AUTOSAR XML (schema 4-2-2)
package /Pack_sw_Types
  constant specification CONST_0c0f918b8f394b8586f853bd5: value-spec=CONST_0c0f918b8f394b8586f853bd5:0
  constant specification CONST_951406b330e947ed9394eb477: value-spec=CONST_951406b330e947ed9394eb477:0
  impl type ComM_ModeType: compu {0=NO_COMMUNICATION, 1=SILENT_COMMUNICATION, 2=FULL_COMMUNICATION}, implementation-data-type=uint8
package /RootP_CS
  4 x client server interface:
    ComM_UserRequest: is-service=true
      operation RequestComMode: possible-error=[E_MODE_LIMITATION, E_NOT_OK]
        arg ComMode: type=ComM_ModeType, direction=IN
      error E_MODE_LIMITATION: error-code=2
      error E_NOT_OK: error-code=1
    DETService: is-service=true
      operation ReportError: possible-error=E_OK
        arg InstanceId: type=uint8, direction=IN
        arg ApiId: type=uint8, direction=IN
        arg ErrorId: type=uint8, direction=IN
      error E_OK: error-code=0
    If_CounterModify
      operation SetCounterAndAdd
        arg newCounterValue: type=uint8, direction=IN
        arg returnSum: type=uint8, direction=OUT
    If_DiscreteValueOutput
      operation SetDiscreteValue
        arg value: type=uint8, direction=IN
package /RootP_SR_Data
  sender receiver interface If_Counter
    data CounterValue: type=uint8
  sender receiver interface If_Internal
    data EventMessage: sw-impl-policy=QUEUED, type=uint8
package /RootP_SWC_CyclicCounter
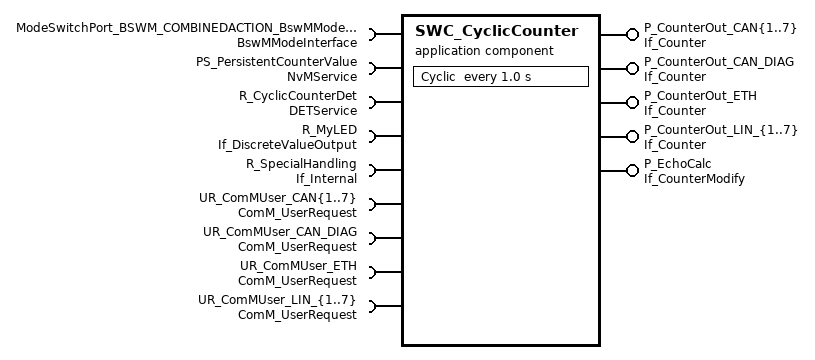
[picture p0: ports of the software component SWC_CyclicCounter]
  application sw component type SWC_CyclicCounter
    require port ModeSwitchPort_BSWM_COMBINEDACTION_BswMMode_PortInterfaces_BswMMode: required-interface=BswMModeInterface
    require port PS_PersistentCounterValue: required-interface=NvMService
    17 x provide port:
      P_CounterOut_CAN{1..7}: nonqueued-sender-com-spec{data-element=CounterValue, init-value=0}, provided-interface=If_Counter
      P_CounterOut_CAN_DIAG: nonqueued-sender-com-spec{data-element=CounterValue, init-value=0}, provided-interface=If_Counter
      P_CounterOut_ETH: nonqueued-sender-com-spec{data-element=CounterValue, init-value=0}, provided-interface=If_Counter
      P_CounterOut_LIN_{1..7}: nonqueued-sender-com-spec{data-element=CounterValue, init-value=0}, provided-interface=If_Counter
      P_EchoCalc: server-com-spec{operation=SetCounterAndAdd, queue-length=1}, provided-interface=If_CounterModify
    19 x require port:
      R_CyclicCounterDet: required-interface=DETService
      R_MyLED: required-interface=If_DiscreteValueOutput
      R_SpecialHandling: queued-receiver-com-spec{data-element=EventMessage, queue-length=8}, required-interface=If_Internal
      UR_ComMUser_CAN{1..7}: required-interface=ComM_UserRequest
      UR_ComMUser_CAN_DIAG: required-interface=ComM_UserRequest
      UR_ComMUser_ETH: required-interface=ComM_UserRequest
      UR_ComMUser_LIN_{1..7}: required-interface=ComM_UserRequest
    behavior IB_SWC_CyclicCounter: data-type-mapping=BswMModeMapping, handle-termination-and-restart=NO-SUPPORT
      timing event CyclicEvent: start-on-event=Cyclic, period=1.0
        disabled-mode:
          ModeSwitchPort_BSWM_COMBINEDACTION_BswMMode_PortInterfaces_BswMMode.BswMMode.BSWM_GO_OFF_ONE_A
          ModeSwitchPort_BSWM_COMBINEDACTION_BswMMode_PortInterfaces_BswMMode.BswMMode.BSWM_PRP_SHUTDOWN
          ModeSwitchPort_BSWM_COMBINEDACTION_BswMMode_PortInterfaces_BswMMode.BswMMode.BSWM_STARTUP_TWO_A
          ModeSwitchPort_BSWM_COMBINEDACTION_BswMMode_PortInterfaces_BswMMode.BswMMode.BSWM_STARTUP_TWO_B
          ModeSwitchPort_BSWM_COMBINEDACTION_BswMMode_PortInterfaces_BswMMode.BswMMode.BSWM_WAKEUP_TWO
      swc mode switch event ModeSwitchedPrpShutdown: start-on-event=Shutdown, activation=ON-ENTRY, mode=ModeSwitchPort_BSWM_COMBINEDACTION_BswMMode_PortInterfaces_BswMMode.BswMMode.BSWM_PRP_SHUTDOWN
      swc mode switch event ModeSwitchedRunTwo: start-on-event=Init, activation=ON-ENTRY, mode=ModeSwitchPort_BSWM_COMBINEDACTION_BswMMode_PortInterfaces_BswMMode.BswMMode.BSWM_RUN_TWO
      operation invoked event SetCounterOperationInvoked: start-on-event=SetCounter, operation=P_EchoCalc.SetCounterAndAdd
      explicit-inter-runnable-variables:
        data CurrentCounterValue: type=uint8, init-value=0
      per instance memory PimCounterValue: init-value=99, type=CounterValueType, type-definition=uint8
      per-instance-parameters:
        parameter data prototype PrmCounterValue: type=uint8, init-value=99
      port-api-options:
        enable-take-address=false, indirect-api=false, port=P_EchoCalc
        enable-take-address=false, indirect-api=false, port=P_CounterOut_CAN{1..7}
        enable-take-address=false, indirect-api=false, port=P_CounterOut_CAN_DIAG
        enable-take-address=false, indirect-api=false, port=P_CounterOut_LIN_{1..7}
        enable-take-address=false, indirect-api=false, port=P_CounterOut_ETH
      4 x runnable:
        Cyclic: symbol=SWC_CyclicCounter_Cyclic
          data-receive-point-by-arguments:
            access DRP_P_Special_EventMessage: accessed-variable=R_SpecialHandling.EventMessage
          data-send-points:
            16 x access:
              DWA_P_CounterOut_CAN{1..7}_CounterValue: accessed-variable=P_CounterOut_CAN{1..7}.CounterValue
              DWA_P_CounterOut_CAN_DIAG_CounterValue: accessed-variable=P_CounterOut_CAN_DIAG.CounterValue
              DWA_P_CounterOut_ETH_CounterValue: accessed-variable=P_CounterOut_ETH.CounterValue
              DWA_P_CounterOut_LIN_{1..7}_CounterValue: accessed-variable=P_CounterOut_LIN_{1..7}.CounterValue
          read-local-variables:
            access CurrentCounterValue3: accessed-variable=CurrentCounterValue
          18 x sync call, all with timeout=0.0:
            CS_DETService_ReportError: operation=R_CyclicCounterDet.ReportError
            CS_EchoResult_SetCounterAndAdd: operation=R_MyLED.SetDiscreteValue
            CS_UR_ComMUser_CAN{1..7}_ComM_UserRequest: operation=UR_ComMUser_CAN{1..7}.RequestComMode
            CS_UR_ComMUser_CAN_DIAG_ComM_UserRequest: operation=UR_ComMUser_CAN_DIAG.RequestComMode
            CS_UR_ComMUser_ETH_ComM_UserRequest: operation=UR_ComMUser_ETH.RequestComMode
            CS_UR_ComMUser_LIN_{1..7}_ComM_UserRequest: operation=UR_ComMUser_LIN_{1..7}.RequestComMode
          written-local-variables:
            access CurrentCounterValue4: accessed-variable=CurrentCounterValue
        Init: symbol=SWC_CyclicCounter_Init
          parameter access PA_PersistentCounterValue: accessed-parameter=PrmCounterValue
          16 x sync call, all with timeout=0.0:
            CS_UR_ComMUser_CAN{1..7}_ComM_UserRequest: operation=UR_ComMUser_CAN{1..7}.RequestComMode
            CS_UR_ComMUser_CAN_DIAG_ComM_UserRequest: operation=UR_ComMUser_CAN_DIAG.RequestComMode
            CS_UR_ComMUser_ETH_ComM_UserRequest: operation=UR_ComMUser_ETH.RequestComMode
            CS_UR_ComMUser_LIN_{1..7}_ComM_UserRequest: operation=UR_ComMUser_LIN_{1..7}.RequestComMode
          written-local-variables:
            access CurrentCounterValue: accessed-variable=CurrentCounterValue
        SetCounter: can-be-invoked-concurrently=true, symbol=SWC_CyclicCounter_SetCounter
          read-local-variables:
            access CurrentCounterValue1: accessed-variable=CurrentCounterValue
          written-local-variables:
            access CurrentCounterValue2: accessed-variable=CurrentCounterValue
        Shutdown: symbol=SWC_CyclicCounter_Shutdown
          read-local-variables:
            access CurrentCounterValue3: accessed-variable=CurrentCounterValue
package /RootP_SWC_IoHwAbs
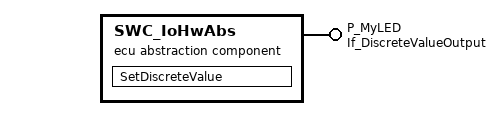
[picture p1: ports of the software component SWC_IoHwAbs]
  ecu abstraction sw component type SWC_IoHwAbs
    provide port P_MyLED: server-com-spec{operation=SetDiscreteValue, queue-length=1}, provided-interface=If_DiscreteValueOutput
    behavior IB_SWC_IoHwAbs: handle-termination-and-restart=NO-SUPPORT, port-api-option{enable-take-address=false, indirect-api=false, port-defined-argument-value{value=0, value-type=uint32}, port=P_MyLED}
      operation invoked event SetDiscreteValueOperationInvoked: start-on-event=SetDiscreteValue, operation=P_MyLED.SetDiscreteValue
      runnable SetDiscreteValue: can-be-invoked-concurrently=true, symbol=SWC_IoHwAbs_SetDiscreteValue
package /RootP_SWC_ModifEcho
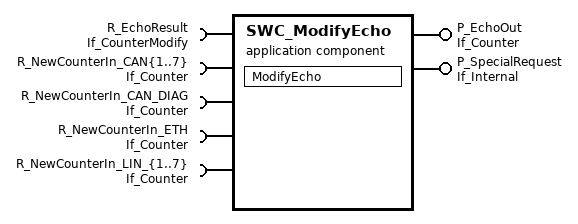
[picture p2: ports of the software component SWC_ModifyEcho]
  application sw component type SWC_ModifyEcho
    provide port P_EchoOut: nonqueued-sender-com-spec{data-element=CounterValue, init-value=0}, provided-interface=If_Counter
    provide port P_SpecialRequest: provided-interface=If_Internal
    17 x require port:
      R_EchoResult: required-interface=If_CounterModify
      R_NewCounterIn_CAN{1..7}: nonqueued-receiver-com-spec{data-element=CounterValue, init-value=constant-reference=CONST_0c0f918b8f394b8586f853bd5}, required-interface=If_Counter
      R_NewCounterIn_CAN_DIAG: nonqueued-receiver-com-spec{data-element=CounterValue, init-value=constant-reference=CONST_0c0f918b8f394b8586f853bd5}, required-interface=If_Counter
      R_NewCounterIn_ETH: nonqueued-receiver-com-spec{data-element=CounterValue, init-value=constant-reference=CONST_0c0f918b8f394b8586f853bd5}, required-interface=If_Counter
      R_NewCounterIn_LIN_{1..7}: nonqueued-receiver-com-spec{data-element=CounterValue, init-value=constant-reference=CONST_0c0f918b8f394b8586f853bd5}, required-interface=If_Counter
    behavior IB_SWC_ModifyEcho: handle-termination-and-restart=NO-SUPPORT
      data received event DataReceivedEvent: start-on-event=ModifyEcho, data=R_NewCounterIn_CAN_DIAG.CounterValue
      port-api-options:
        enable-take-address=false, indirect-api=false, port=R_EchoResult
        enable-take-address=false, indirect-api=false, port=R_NewCounterIn_CAN_DIAG
        enable-take-address=false, indirect-api=false, port=P_EchoOut
      runnable ModifyEcho: symbol=SWC_ModifyEcho_ModifyEcho
        data-receive-point-by-arguments:
          access DRP_R_NewCounterIn_CounterValue: accessed-variable=R_NewCounterIn_CAN_DIAG.CounterValue
        data-send-points:
          access DSP_P_Special_EventMessage: accessed-variable=P_SpecialRequest.EventMessage
        data-write-access:
          access DWA_P_EchoOut_CounterValue: accessed-variable=P_EchoOut.CounterValue
        sync call CS_EchoResult_SetCounterAndAdd: operation=R_EchoResult.SetCounterAndAdd, timeout=0.0
package /SwcImplementations
  swc implementation Impl_SWC_CyclicCounter: programming-language=C, sw-version=1.0.0, vendor-id=1, behavior=IB_SWC_CyclicCounter
    code-descriptors:
      code SRC: artifact-descriptors=autosar-engineering-object={short-label=EngObject, category=SWSRC}
    resource consumption Resources
  swc implementation Impl_SWC_IoHwAbs: programming-language=C, sw-version=1.0.0, vendor-id=1, behavior=IB_SWC_IoHwAbs
    code-descriptors:
      code SRC: artifact-descriptors=autosar-engineering-object={short-label=EngObject, category=SWSRC}
    resource consumption Resources
  swc implementation Impl_SWC_ModifyEcho: programming-language=C, sw-version=1.0.0, vendor-id=1, behavior=IB_SWC_ModifyEcho
    code-descriptors:
      code SRC: artifact-descriptors=autosar-engineering-object={short-label=EngObject, category=SWSRC}
    resource consumption Resources
